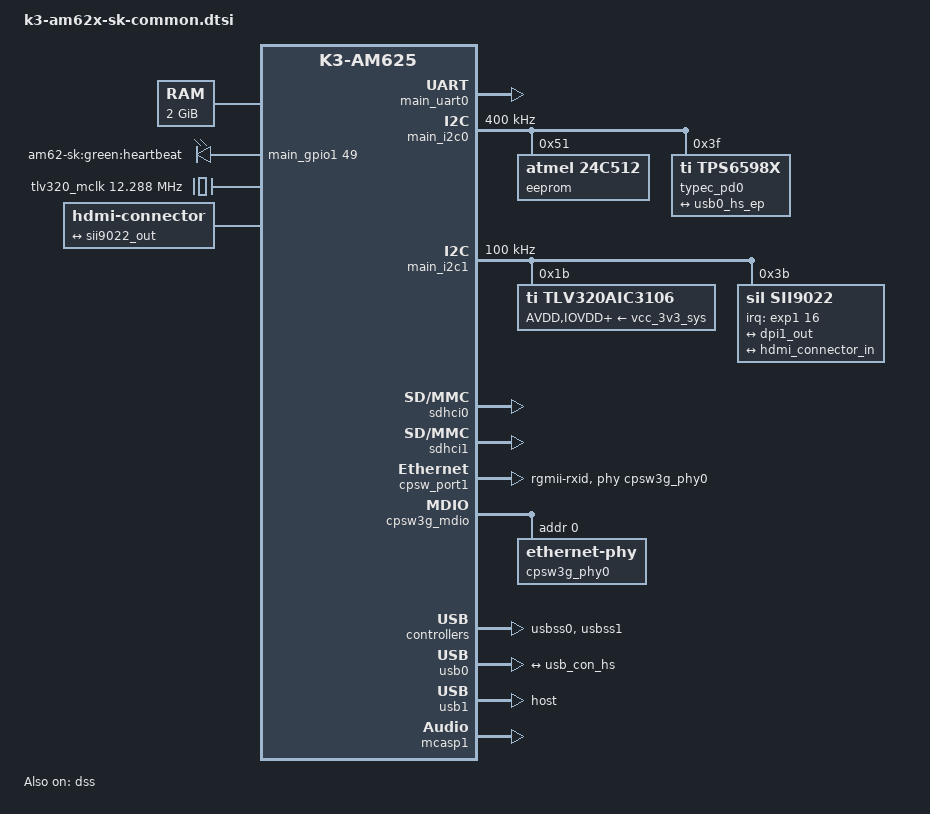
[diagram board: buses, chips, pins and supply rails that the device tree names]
#include <dt-bindings/leds/common.h>
#include <dt-bindings/gpio/gpio.h>
#include <dt-bindings/net/ti-dp83867.h>
#include "k3-am625.dtsi"
/ {
	aliases {
		serial2 = &main_uart0;
		mmc0 = &sdhci0;
		mmc1 = &sdhci1;
		mmc2 = &sdhci2;
		spi0 = &ospi0;
		ethernet0 = &cpsw_port1;
		ethernet1 = &cpsw_port2;
		usb0 = &usb0;
		usb1 = &usb1;
	};
	chosen {
		stdout-path = "serial2:115200n8";
	};
	memory@80000000 {
		device_type = "memory";
		reg = <0x00000000 0x80000000 0x00000000 0x80000000>;
	};
	reserved-memory {
		#address-cells = <2>;
		#size-cells = <2>;
		ranges;
		ramoops@9ca00000 {
			compatible = "ramoops";
			reg = <0x00 0x9ca00000 0x00 0x00100000>;
			record-size = <0x8000>;
			console-size = <0x8000>;
			ftrace-size = <0x00>;
			pmsg-size = <0x8000>;
		};
		secure_tfa_ddr: tfa@9e780000 {
			reg = <0x00 0x9e780000 0x00 0x80000>;
			alignment = <0x1000>;
			no-map;
		};
		secure_ddr: optee@9e800000 {
			reg = <0x00 0x9e800000 0x00 0x01800000>;  
			alignment = <0x1000>;
			no-map;
		};
		wkup_r5fss0_core0_dma_memory_region: r5f-dma-memory@9db00000 {
			compatible = "shared-dma-pool";
			reg = <0x00 0x9db00000 0x00 0xc00000>;
			no-map;
		};
	};
	leds {
		compatible = "gpio-leds";
		pinctrl-names = "default";
		pinctrl-0 = <&usr_led_pins_default>;
		led-0 {
			label = "am62-sk:green:heartbeat";
			gpios = <&main_gpio1 49 GPIO_ACTIVE_HIGH>;
			linux,default-trigger = "heartbeat";
			function = LED_FUNCTION_HEARTBEAT;
			default-state = "off";
		};
	};
	tlv320_mclk: clk-0 {
		#clock-cells = <0>;
		compatible = "fixed-clock";
		clock-frequency = <12288000>;
	};
	codec_audio: sound {
		compatible = "simple-audio-card";
		simple-audio-card,name = "AM62x-SKEVM";
		simple-audio-card,widgets =
			"Headphone",	"Headphone Jack",
			"Line",		"Line In",
			"Microphone",	"Microphone Jack";
		simple-audio-card,routing =
			"Headphone Jack",	"HPLOUT",
			"Headphone Jack",	"HPROUT",
			"LINE1L",		"Line In",
			"LINE1R",		"Line In",
			"MIC3R",		"Microphone Jack",
			"Microphone Jack",	"Mic Bias";
		simple-audio-card,format = "dsp_b";
		simple-audio-card,bitclock-master = <&sound_master>;
		simple-audio-card,frame-master = <&sound_master>;
		simple-audio-card,bitclock-inversion;
		simple-audio-card,cpu {
			sound-dai = <&mcasp1>;
		};
		sound_master: simple-audio-card,codec {
			sound-dai = <&tlv320aic3106>;
			clocks = <&tlv320_mclk>;
		};
	};
	hdmi0: connector-hdmi {
		compatible = "hdmi-connector";
		label = "hdmi";
		type = "a";
		port {
			hdmi_connector_in: endpoint {
				remote-endpoint = <&sii9022_out>;
			};
		};
	};
};
&main_pmx0 {
	main_uart0_pins_default: main-uart0-default-pins {
		pinctrl-single,pins = <
			AM62X_IOPAD(0x1c8, PIN_INPUT, 0)  
			AM62X_IOPAD(0x1cc, PIN_OUTPUT, 0)  
		>;
	};
	main_uart1_pins_default: main-uart1-default-pins {
		pinctrl-single,pins = <
			AM62X_IOPAD(0x194, PIN_INPUT, 2)  
			AM62X_IOPAD(0x198, PIN_OUTPUT, 2)  
			AM62X_IOPAD(0x1ac, PIN_INPUT, 2)  
			AM62X_IOPAD(0x1b0, PIN_OUTPUT, 2)  
		>;
	};
	main_i2c0_pins_default: main-i2c0-default-pins {
		pinctrl-single,pins = <
			AM62X_IOPAD(0x1e0, PIN_INPUT_PULLUP, 0)  
			AM62X_IOPAD(0x1e4, PIN_INPUT_PULLUP, 0)  
		>;
	};
	main_i2c1_pins_default: main-i2c1-default-pins {
		pinctrl-single,pins = <
			AM62X_IOPAD(0x1e8, PIN_INPUT_PULLUP, 0)  
			AM62X_IOPAD(0x1ec, PIN_INPUT_PULLUP, 0)  
		>;
	};
	main_i2c2_pins_default: main-i2c2-default-pins {
		pinctrl-single,pins = <
			AM62X_IOPAD(0x0b0, PIN_INPUT_PULLUP, 1)  
			AM62X_IOPAD(0x0b4, PIN_INPUT_PULLUP, 1)  
		>;
	};
	main_mmc0_pins_default: main-mmc0-default-pins {
		pinctrl-single,pins = <
			AM62X_IOPAD(0x220, PIN_INPUT, 0)  
			AM62X_IOPAD(0x218, PIN_INPUT, 0)  
			AM62X_IOPAD(0x214, PIN_INPUT, 0)  
			AM62X_IOPAD(0x210, PIN_INPUT, 0)  
			AM62X_IOPAD(0x20c, PIN_INPUT, 0)  
			AM62X_IOPAD(0x208, PIN_INPUT, 0)  
			AM62X_IOPAD(0x204, PIN_INPUT, 0)  
			AM62X_IOPAD(0x200, PIN_INPUT, 0)  
			AM62X_IOPAD(0x1fc, PIN_INPUT, 0)  
			AM62X_IOPAD(0x1f8, PIN_INPUT, 0)  
		>;
	};
	main_mmc1_pins_default: main-mmc1-default-pins {
		pinctrl-single,pins = <
			AM62X_IOPAD(0x23c, PIN_INPUT, 0)  
			AM62X_IOPAD(0x234, PIN_INPUT, 0)  
			AM62X_IOPAD(0x230, PIN_INPUT, 0)  
			AM62X_IOPAD(0x22c, PIN_INPUT, 0)  
			AM62X_IOPAD(0x228, PIN_INPUT, 0)  
			AM62X_IOPAD(0x224, PIN_INPUT, 0)  
			AM62X_IOPAD(0x240, PIN_INPUT, 0)  
		>;
	};
	usr_led_pins_default: usr-led-default-pins {
		pinctrl-single,pins = <
			AM62X_IOPAD(0x244, PIN_OUTPUT, 7)  
		>;
	};
	main_mdio1_pins_default: main-mdio1-default-pins {
		pinctrl-single,pins = <
			AM62X_IOPAD(0x160, PIN_OUTPUT, 0)  
			AM62X_IOPAD(0x15c, PIN_INPUT, 0)  
		>;
	};
	main_rgmii1_pins_default: main-rgmii1-default-pins {
		pinctrl-single,pins = <
			AM62X_IOPAD(0x14c, PIN_INPUT, 0)  
			AM62X_IOPAD(0x150, PIN_INPUT, 0)  
			AM62X_IOPAD(0x154, PIN_INPUT, 0)  
			AM62X_IOPAD(0x158, PIN_INPUT, 0)  
			AM62X_IOPAD(0x148, PIN_INPUT, 0)  
			AM62X_IOPAD(0x144, PIN_INPUT, 0)  
			AM62X_IOPAD(0x134, PIN_OUTPUT, 0)  
			AM62X_IOPAD(0x138, PIN_OUTPUT, 0)  
			AM62X_IOPAD(0x13c, PIN_OUTPUT, 0)  
			AM62X_IOPAD(0x140, PIN_OUTPUT, 0)  
			AM62X_IOPAD(0x130, PIN_OUTPUT, 0)  
			AM62X_IOPAD(0x12c, PIN_OUTPUT, 0)  
		>;
	};
	main_usb1_pins_default: main-usb1-default-pins {
		pinctrl-single,pins = <
			AM62X_IOPAD(0x0258, PIN_OUTPUT, 0)  
		>;
	};
	main_mcasp1_pins_default: main-mcasp1-default-pins {
		pinctrl-single,pins = <
			AM62X_IOPAD(0x090, PIN_INPUT, 2)  
			AM62X_IOPAD(0x098, PIN_INPUT, 2)  
			AM62X_IOPAD(0x08c, PIN_OUTPUT, 2)  
			AM62X_IOPAD(0x084, PIN_INPUT, 2)  
		>;
	};
	main_dss0_pins_default: main-dss0-default-pins {
		pinctrl-single,pins = <
			AM62X_IOPAD(0x100, PIN_OUTPUT, 0)  
			AM62X_IOPAD(0x0f8, PIN_OUTPUT, 0)  
			AM62X_IOPAD(0x104, PIN_OUTPUT, 0)  
			AM62X_IOPAD(0x0fc, PIN_OUTPUT, 0)  
			AM62X_IOPAD(0x0b8, PIN_OUTPUT, 0)  
			AM62X_IOPAD(0x0bc, PIN_OUTPUT, 0)  
			AM62X_IOPAD(0x0c0, PIN_OUTPUT, 0)  
			AM62X_IOPAD(0x0c4, PIN_OUTPUT, 0)  
			AM62X_IOPAD(0x0c8, PIN_OUTPUT, 0)  
			AM62X_IOPAD(0x0cc, PIN_OUTPUT, 0)  
			AM62X_IOPAD(0x0d0, PIN_OUTPUT, 0)  
			AM62X_IOPAD(0x0d4, PIN_OUTPUT, 0)  
			AM62X_IOPAD(0x0d8, PIN_OUTPUT, 0)  
			AM62X_IOPAD(0x0dc, PIN_OUTPUT, 0)  
			AM62X_IOPAD(0x0e0, PIN_OUTPUT, 0)  
			AM62X_IOPAD(0x0e4, PIN_OUTPUT, 0)  
			AM62X_IOPAD(0x0e8, PIN_OUTPUT, 0)  
			AM62X_IOPAD(0x0ec, PIN_OUTPUT, 0)  
			AM62X_IOPAD(0x0f0, PIN_OUTPUT, 0)  
			AM62X_IOPAD(0x0f4, PIN_OUTPUT, 0)  
			AM62X_IOPAD(0x05c, PIN_OUTPUT, 1)  
			AM62X_IOPAD(0x060, PIN_OUTPUT, 1)  
			AM62X_IOPAD(0x064, PIN_OUTPUT, 1)  
			AM62X_IOPAD(0x068, PIN_OUTPUT, 1)  
			AM62X_IOPAD(0x06c, PIN_OUTPUT, 1)  
			AM62X_IOPAD(0x070, PIN_OUTPUT, 1)  
			AM62X_IOPAD(0x074, PIN_OUTPUT, 1)  
			AM62X_IOPAD(0x078, PIN_OUTPUT, 1)  
		>;
	};
};
&mcu_pmx0 {
	wkup_uart0_pins_default: wkup-uart0-default-pins {
		pinctrl-single,pins = <
			AM62X_MCU_IOPAD(0x02c, PIN_INPUT, 0)  
			AM62X_MCU_IOPAD(0x030, PIN_OUTPUT, 0)  
			AM62X_MCU_IOPAD(0x024, PIN_INPUT, 0)  
			AM62X_MCU_IOPAD(0x028, PIN_OUTPUT, 0)  
		>;
	};
};
&wkup_uart0 {
	status = "reserved";
	pinctrl-names = "default";
	pinctrl-0 = <&wkup_uart0_pins_default>;
};
&main_uart0 {
	status = "okay";
	pinctrl-names = "default";
	pinctrl-0 = <&main_uart0_pins_default>;
};
&main_uart1 {
	status = "reserved";
	pinctrl-names = "default";
	pinctrl-0 = <&main_uart1_pins_default>;
};
&main_i2c0 {
	status = "okay";
	pinctrl-names = "default";
	pinctrl-0 = <&main_i2c0_pins_default>;
	clock-frequency = <400000>;
	eeprom@51 {
		compatible = "atmel,24c512";
		reg = <0x51>;
	};
	typec_pd0: tps6598x@3f {
		compatible = "ti,tps6598x";
		reg = <0x3f>;
		connector {
			compatible = "usb-c-connector";
			label = "USB-C";
			self-powered;
			data-role = "dual";
			power-role = "sink";
			ports {
				#address-cells = <1>;
				#size-cells = <0>;
				port@0 {
					reg = <0>;
					usb_con_hs: endpoint {
						remote-endpoint = <&usb0_hs_ep>;
					};
				};
			};
		};
	};
};
&main_i2c1 {
	status = "okay";
	pinctrl-names = "default";
	pinctrl-0 = <&main_i2c1_pins_default>;
	clock-frequency = <100000>;
	tlv320aic3106: audio-codec@1b {
		#sound-dai-cells = <0>;
		compatible = "ti,tlv320aic3106";
		reg = <0x1b>;
		ai3x-micbias-vg = <1>;	 
		AVDD-supply = <&vcc_3v3_sys>;
		IOVDD-supply = <&vcc_3v3_sys>;
		DRVDD-supply = <&vcc_3v3_sys>;
	};
	sii9022: bridge-hdmi@3b {
		compatible = "sil,sii9022";
		reg = <0x3b>;
		interrupt-parent = <&exp1>;
		interrupts = <16 IRQ_TYPE_EDGE_FALLING>;
		#sound-dai-cells = <0>;
		sil,i2s-data-lanes = < 0 >;
		ports {
			#address-cells = <1>;
			#size-cells = <0>;
			port@0 {
				reg = <0>;
				sii9022_in: endpoint {
					remote-endpoint = <&dpi1_out>;
				};
			};
			port@1 {
				reg = <1>;
				sii9022_out: endpoint {
					remote-endpoint = <&hdmi_connector_in>;
				};
			};
		};
	};
};
&sdhci0 {
	status = "okay";
	pinctrl-names = "default";
	pinctrl-0 = <&main_mmc0_pins_default>;
	ti,driver-strength-ohm = <50>;
	disable-wp;
};
&sdhci1 {
	status = "okay";
	pinctrl-names = "default";
	pinctrl-0 = <&main_mmc1_pins_default>;
	ti,driver-strength-ohm = <50>;
	disable-wp;
};
&cpsw3g {
	pinctrl-names = "default";
	pinctrl-0 = <&main_rgmii1_pins_default>;
};
&cpsw_port1 {
	phy-mode = "rgmii-rxid";
	phy-handle = <&cpsw3g_phy0>;
};
&cpsw3g_mdio {
	status = "okay";
	pinctrl-names = "default";
	pinctrl-0 = <&main_mdio1_pins_default>;
	cpsw3g_phy0: ethernet-phy@0 {
		reg = <0>;
		ti,rx-internal-delay = <DP83867_RGMIIDCTL_2_00_NS>;
		ti,fifo-depth = <DP83867_PHYCR_FIFO_DEPTH_4_B_NIB>;
		ti,min-output-impedance;
	};
};
&mailbox0_cluster0 {
	mbox_m4_0: mbox-m4-0 {
		ti,mbox-rx = <0 0 0>;
		ti,mbox-tx = <1 0 0>;
	};
};
&usbss0 {
	status = "okay";
	ti,vbus-divider;
};
&usbss1 {
	status = "okay";
	ti,vbus-divider;
};
&usb0 {
	#address-cells = <1>;
	#size-cells = <0>;
	usb-role-switch;
	port@0 {
		reg = <0>;
		usb0_hs_ep: endpoint {
		    remote-endpoint = <&usb_con_hs>;
	       };
	};
};
&usb1 {
	dr_mode = "host";
	pinctrl-names = "default";
	pinctrl-0 = <&main_usb1_pins_default>;
};
&mcasp1 {
	status = "okay";
	#sound-dai-cells = <0>;
	pinctrl-names = "default";
	pinctrl-0 = <&main_mcasp1_pins_default>;
	op-mode = <0>;           
	tdm-slots = <2>;
	serial-dir = <   
	       1 0 2 0
	       0 0 0 0
	       0 0 0 0
	       0 0 0 0
	>;
	tx-num-evt = <32>;
	rx-num-evt = <32>;
};
&dss {
	status = "okay";
	pinctrl-names = "default";
	pinctrl-0 = <&main_dss0_pins_default>;
};
&dss_ports {
	port@1 {
		reg = <1>;
		dpi1_out: endpoint {
			remote-endpoint = <&sii9022_in>;
		};
	};
};
